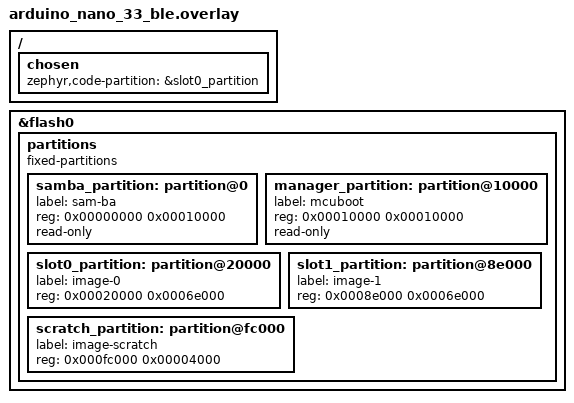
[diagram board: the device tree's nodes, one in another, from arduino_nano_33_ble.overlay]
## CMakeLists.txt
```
cmake_minimum_required(VERSION 3.20.0)
find_package(Zephyr REQUIRED HINTS $ENV{ZEPHYR_BASE})
project(mower_ota_test_app)

target_sources(app PRIVATE src/main.c)
```

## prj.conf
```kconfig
CONFIG_BOOTLOADER_MCUBOOT=y
CONFIG_MCUBOOT_GENERATE_UNSIGNED_IMAGE=y
CONFIG_GPIO=y
CONFIG_CONSOLE=n
CONFIG_UART_CONSOLE=n
```

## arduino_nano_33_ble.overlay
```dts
/ {
	chosen {
		zephyr,code-partition = &slot0_partition;
	};
};

&flash0 {
	/delete-node/ partitions;

	partitions {
		compatible = "fixed-partitions";
		#address-cells = <1>;
		#size-cells = <1>;

		samba_partition: partition@0 {
			label = "sam-ba";
			reg = <0x00000000 0x00010000>;
			read-only;
		};

		manager_partition: partition@10000 {
			label = "mcuboot";
			reg = <0x00010000 0x00010000>;
			read-only;
		};

		slot0_partition: partition@20000 {
			label = "image-0";
			reg = <0x00020000 0x0006e000>;
		};

		slot1_partition: partition@8e000 {
			label = "image-1";
			reg = <0x0008e000 0x0006e000>;
		};

		scratch_partition: partition@fc000 {
			label = "image-scratch";
			reg = <0x000fc000 0x00004000>;
		};
	};
};
```

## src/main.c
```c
#include <zephyr/kernel.h>
#include <zephyr/drivers/gpio.h>

static const struct gpio_dt_spec led = GPIO_DT_SPEC_GET(DT_ALIAS(led0), gpios);

int main(void)
{
	if (!gpio_is_ready_dt(&led)) {
		return 0;
	}

	gpio_pin_configure_dt(&led, GPIO_OUTPUT_INACTIVE);

	for (;;) {
		gpio_pin_toggle_dt(&led);
		k_sleep(K_MSEC(500));
	}

	return 0;
}
```
